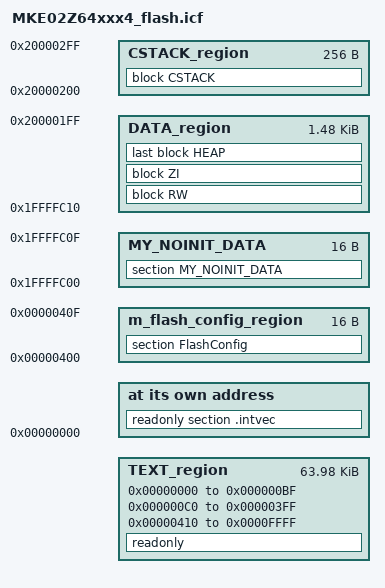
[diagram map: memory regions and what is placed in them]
/*
** ###################################################################
**     Processors:          MKE02Z64VFM4
**                          MKE02Z64VLC4
**                          MKE02Z64VLD4
**                          MKE02Z64VLH4
**                          MKE02Z64VQH4
**
**     Compiler:            IAR ANSI C/C++ Compiler for ARM
**     Reference manual:    MKE02P64M40SF0RM Rev 4
**     Version:             rev. 1.0, 2017-05-19
**     Build:               b170817
**
**     Abstract:
**         Linker file for the IAR ANSI C/C++ Compiler for ARM
**
**     Copyright 2016 Freescale Semiconductor, Inc.
**     Copyright 2016-2017 NXP
**     Redistribution and use in source and binary forms, with or without modification,
**     are permitted provided that the following conditions are met:
**
**     1. Redistributions of source code must retain the above copyright notice, this list
**       of conditions and the following disclaimer.
**
**     2. Redistributions in binary form must reproduce the above copyright notice, this
**       list of conditions and the following disclaimer in the documentation and/or
**       other materials provided with the distribution.
**
**     3. Neither the name of the copyright holder nor the names of its
**       contributors may be used to endorse or promote products derived from this
**       software without specific prior written permission.
**
**     THIS SOFTWARE IS PROVIDED BY THE COPYRIGHT HOLDERS AND CONTRIBUTORS "AS IS" AND
**     ANY EXPRESS OR IMPLIED WARRANTIES, INCLUDING, BUT NOT LIMITED TO, THE IMPLIED
**     WARRANTIES OF MERCHANTABILITY AND FITNESS FOR A PARTICULAR PURPOSE ARE
**     DISCLAIMED. IN NO EVENT SHALL THE COPYRIGHT HOLDER OR CONTRIBUTORS BE LIABLE FOR
**     ANY DIRECT, INDIRECT, INCIDENTAL, SPECIAL, EXEMPLARY, OR CONSEQUENTIAL DAMAGES
**     (INCLUDING, BUT NOT LIMITED TO, PROCUREMENT OF SUBSTITUTE GOODS OR SERVICES;
**     LOSS OF USE, DATA, OR PROFITS; OR BUSINESS INTERRUPTION) HOWEVER CAUSED AND ON
**     ANY THEORY OF LIABILITY, WHETHER IN CONTRACT, STRICT LIABILITY, OR TORT
**     (INCLUDING NEGLIGENCE OR OTHERWISE) ARISING IN ANY WAY OUT OF THE USE OF THIS
**     SOFTWARE, EVEN IF ADVISED OF THE POSSIBILITY OF SUCH DAMAGE.
**
**     http:                 www.nxp.com
**     mail:                 support@nxp.com
**
** ###################################################################
*/


define symbol m_interrupts_start       = 0x00000000;
//define symbol m_interrupts_end         = 0x000001FF;
define symbol m_interrupts_end         = 0x00000BF;

define symbol m_text_start_0           = 0x000000C0;
define symbol m_text_end_0             = 0x000003FF;

define symbol m_flash_config_start     = 0x00000400;
define symbol m_flash_config_end       = 0x0000040F;

define symbol m_text_start             = 0x00000410;
define symbol m_text_end               = 0x0000FFFF;

define symbol m_noinit_start           = 0x1FFFFC00;
define symbol m_noinit_end             = 0x1FFFFC0F;

define symbol m_data_start             = 0x1FFFFC10;
define symbol m_data_end               = 0x200002FF;
//define symbol m_data_end               = 0x20000BFF; // max...

/* Sizes */
if (isdefinedsymbol(__stack_size__)) {
  define symbol __size_cstack__        = __stack_size__;
} else {
  define symbol __size_cstack__        = 0x0100;
}

if (isdefinedsymbol(__heap_size__)) {
  define symbol __size_heap__          = __heap_size__;
} else {
  //define symbol __size_heap__          = 0x0100;
  define symbol __size_heap__          = 0x0;
}


define memory mem with size = 4G;
define region TEXT_region = mem:[from m_interrupts_start to m_interrupts_end] | mem:[from m_text_start_0 to m_text_end_0] | mem:[from m_text_start to m_text_end];
define region m_flash_config_region = mem:[from m_flash_config_start to m_flash_config_end];
define region DATA_region = mem:[from m_data_start to m_data_end-__size_cstack__];

define region MY_NOINIT_DATA = mem:[from m_noinit_start to m_noinit_end];  // prima definire una regione....

define region CSTACK_region = mem:[from m_data_end-__size_cstack__+1 to m_data_end];

define block CSTACK    with alignment = 8, size = __size_cstack__   { };
define block HEAP      with alignment = 8, size = __size_heap__     { };
define block RW        { readwrite };
define block ZI        { zi };

initialize by copy { readwrite, section .textrw };
do not initialize  { section .noinit };

do not initialize  { section MY_NOINIT_DATA };     // poi dirgli di non inizializzarla...

place at address mem: m_interrupts_start    { readonly section .intvec };
place in m_flash_config_region              { section FlashConfig };

place in MY_NOINIT_DATA                     { section MY_NOINIT_DATA };    // poi il piazzamento che serve per la direttiva #pragma location = "NOINIT_DATA" attenzione solo la "location" funziona la "section" no...

place in TEXT_region                        { readonly };
place in DATA_region                        { block RW };
place in DATA_region                        { block ZI };
place in DATA_region                        { last block HEAP };
place in CSTACK_region                      { block CSTACK };

